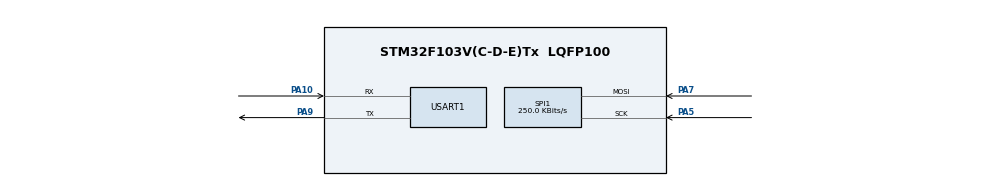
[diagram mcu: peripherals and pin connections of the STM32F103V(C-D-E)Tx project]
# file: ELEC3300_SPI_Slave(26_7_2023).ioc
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Mcu.Family=STM32F1
Mcu.Name=STM32F103V(C-D-E)Tx
Mcu.Package=LQFP100
NVIC.PriorityGroup=NVIC_PRIORITYGROUP_4
OSC_IN.Mode=HSE-External-Oscillator
OSC_IN.Signal=RCC_OSC_IN
OSC_OUT.Mode=HSE-External-Oscillator
OSC_OUT.Signal=RCC_OSC_OUT
PA10.Mode=Asynchronous
PA10.Signal=USART1_RX
PA13.Mode=Serial_Wire
PA13.Signal=SYS_JTMS-SWDIO
PA14.Mode=Serial_Wire
PA14.Signal=SYS_JTCK-SWCLK
PA5.Mode=RX_Only_Simplex_Unidirect_Slave
PA5.Signal=SPI1_SCK
PA7.Mode=RX_Only_Simplex_Unidirect_Slave
PA7.Signal=SPI1_MOSI
PA9.Mode=Asynchronous
PA9.Signal=USART1_TX
PC14-OSC32_IN.Mode=LSE-External-Oscillator
PC14-OSC32_IN.Signal=RCC_OSC32_IN
PC15-OSC32_OUT.Mode=LSE-External-Oscillator
PC15-OSC32_OUT.Signal=RCC_OSC32_OUT
ProjectManager.HeapSize=0x200
ProjectManager.StackSize=0x400
ProjectManager.TargetToolchain=MDK-ARM V5.27
RCC.APB1Freq_Value=8000000
RCC.APB2Freq_Value=8000000
SPI1.BaudRatePrescaler=SPI_BAUDRATEPRESCALER_32
SPI1.CalculateBaudRate=250.0 KBits/s
SPI1.Direction=SPI_DIRECTION_2LINES_RXONLY
SPI1.Mode=SPI_MODE_SLAVE
SPI1.VirtualType=VM_SLAVE
USART1.VirtualMode=VM_ASYNC
board=custom

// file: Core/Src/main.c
/* USER CODE BEGIN Header */
/**
  ******************************************************************************
  * @file           : main.c
  * @brief          : Main program body
  ******************************************************************************
  * @attention
  *
  * <h2><center>&copy; Copyright (c) 2023 STMicroelectronics.
  * All rights reserved.</center></h2>
  *
  * This software component is licensed by ST under BSD 3-Clause license,
  * the "License"; You may not use this file except in compliance with the
  * License. You may obtain a copy of the License at:
  *                        opensource.org/licenses/BSD-3-Clause
  *
  ******************************************************************************
  */
/* USER CODE END Header */
#include "main.h"

SPI_HandleTypeDef hspi1;

UART_HandleTypeDef huart1;

/* USER CODE BEGIN PV */
uint8_t RX_Data[1652] = {0};
/* USER CODE END PV */

void SystemClock_Config(void);
static void MX_GPIO_Init(void);
static void MX_SPI1_Init(void);
static void MX_USART1_UART_Init(void);

int main(void)
{

  /* MCU Configuration--------------------------------------------------------*/

  /* Reset of all peripherals, Initializes the Flash interface and the Systick. */
  HAL_Init();

  /* Configure the system clock */
  SystemClock_Config();

  /* Initialize all configured peripherals */
  MX_GPIO_Init();
  MX_SPI1_Init();
  MX_USART1_UART_Init();
  /* USER CODE BEGIN 2 */
	HAL_SPI_Receive(&hspi1, RX_Data, sizeof(RX_Data), 5000);
  HAL_UART_Transmit(&huart1, RX_Data, sizeof(RX_Data), 5000);

  /* USER CODE END 2 */

  /* Infinite loop */
  while (1)
  {

  }
}

void SystemClock_Config(void)
{
  RCC_OscInitTypeDef RCC_OscInitStruct = {0};
  RCC_ClkInitTypeDef RCC_ClkInitStruct = {0};

  /** Initializes the RCC Oscillators according to the specified parameters
  * in the RCC_OscInitTypeDef structure.
  */
  RCC_OscInitStruct.OscillatorType = RCC_OSCILLATORTYPE_HSI;
  RCC_OscInitStruct.HSIState = RCC_HSI_ON;
  RCC_OscInitStruct.HSICalibrationValue = RCC_HSICALIBRATION_DEFAULT;
  RCC_OscInitStruct.PLL.PLLState = RCC_PLL_NONE;
  if (HAL_RCC_OscConfig(&RCC_OscInitStruct) != HAL_OK)
  {
    Error_Handler();
  }
  /** Initializes the CPU, AHB and APB buses clocks
  */
  RCC_ClkInitStruct.ClockType = RCC_CLOCKTYPE_HCLK|RCC_CLOCKTYPE_SYSCLK
                              |RCC_CLOCKTYPE_PCLK1|RCC_CLOCKTYPE_PCLK2;
  RCC_ClkInitStruct.SYSCLKSource = RCC_SYSCLKSOURCE_HSI;
  RCC_ClkInitStruct.AHBCLKDivider = RCC_SYSCLK_DIV1;
  RCC_ClkInitStruct.APB1CLKDivider = RCC_HCLK_DIV1;
  RCC_ClkInitStruct.APB2CLKDivider = RCC_HCLK_DIV1;

  if (HAL_RCC_ClockConfig(&RCC_ClkInitStruct, FLASH_LATENCY_0) != HAL_OK)
  {
    Error_Handler();
  }
}

static void MX_SPI1_Init(void)
{

  /* SPI1 parameter configuration*/
  hspi1.Instance = SPI1;
  hspi1.Init.Mode = SPI_MODE_SLAVE;
  hspi1.Init.Direction = SPI_DIRECTION_2LINES_RXONLY;
  hspi1.Init.DataSize = SPI_DATASIZE_8BIT;
  hspi1.Init.CLKPolarity = SPI_POLARITY_LOW;
  hspi1.Init.CLKPhase = SPI_PHASE_1EDGE;
  hspi1.Init.NSS = SPI_NSS_SOFT;
  hspi1.Init.BaudRatePrescaler = SPI_BAUDRATEPRESCALER_32;
  hspi1.Init.FirstBit = SPI_FIRSTBIT_MSB;
  hspi1.Init.TIMode = SPI_TIMODE_DISABLE;
  hspi1.Init.CRCCalculation = SPI_CRCCALCULATION_DISABLE;
  hspi1.Init.CRCPolynomial = 10;
  if (HAL_SPI_Init(&hspi1) != HAL_OK)
  {
    Error_Handler();
  }

}

static void MX_USART1_UART_Init(void)
{

  huart1.Instance = USART1;
  huart1.Init.BaudRate = 115200;
  huart1.Init.WordLength = UART_WORDLENGTH_8B;
  huart1.Init.StopBits = UART_STOPBITS_1;
  huart1.Init.Parity = UART_PARITY_NONE;
  huart1.Init.Mode = UART_MODE_TX_RX;
  huart1.Init.HwFlowCtl = UART_HWCONTROL_NONE;
  huart1.Init.OverSampling = UART_OVERSAMPLING_16;
  if (HAL_UART_Init(&huart1) != HAL_OK)
  {
    Error_Handler();
  }

}

static void MX_GPIO_Init(void)
{

  /* GPIO Ports Clock Enable */
  __HAL_RCC_GPIOC_CLK_ENABLE();
  __HAL_RCC_GPIOA_CLK_ENABLE();

}

void Error_Handler(void)
{
  __disable_irq();
  while (1)
  {
  }
}

/************************ (C) COPYRIGHT STMicroelectronics *****END OF FILE****/
